VERSION "HIPBNYYYYYYYYYYYYYYYYYYYYYYYYYYYYYYYYYYYYY/4/%%%/4/'%**4YYY///"

NS_ :

BS_:

BU_: DBG VCU BMS MCM DCU DAQ S2C

BO_ 256 EMeter_Measurement: 8 Vector__XXX
 SG_ EMeter_Current : 7|32@0- (1.5258789063e-005,0) [0|0] "A" Vector__XXX
 SG_ EMeter_Voltage : 39|32@0- (1.5258789063e-005,0) [0|0] "V" Vector__XXX

BO_ 165 MCM_Motor_Position_Info: 8 MCM
 SG_ MCM_Motor_Speed : 16|16@1- (1,0) [-32768|32767] "RPM" VCU

BO_ 166 MCM_Current_Info: 8 MCM
 SG_ MCM_DC_Bus_Current : 48|16@1- (0.1,0) [-3276.8|3276.7] "A" VCU

BO_ 167 MCM_Voltage_Info: 8 MCM
 SG_ MCM_DC_Bus_Voltage : 0|16@1- (0.1,0) [-3276.8|3276.7] "V" VCU

BO_ 170 MCM_Internal_States: 8 MCM
 SG_ MCM_Int_Invert_Enable_State : 48|1@1+ (1,0) [0|1] "" MCM
 SG_ MCM_Int_Inverter_State : 16|8@1+ (1,0) [0|255] "" MCM

BO_ 172 MCM_Torque_And_Timer_Info: 8 MCM
 SG_ MCM_Torque_Feedback : 16|16@1- (0.1,0) [-3276.8|3276.7] "Nm" VCU
 SG_ MCM_Commanded_Torque : 0|16@1- (0.1,0) [-3276.8|3276.7] "Nm" VCU

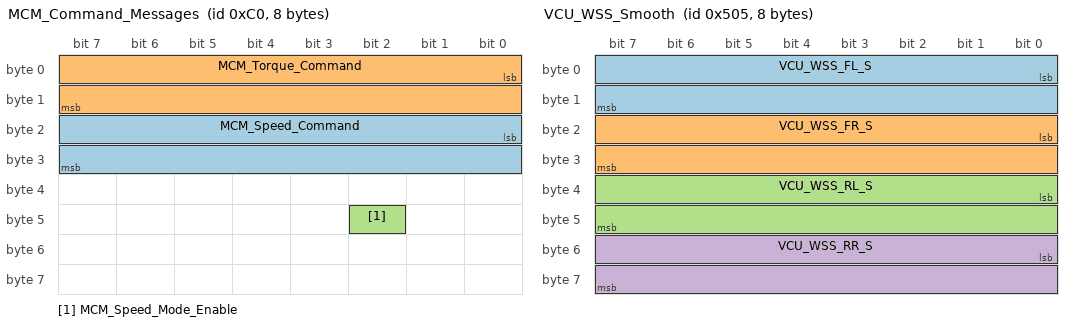
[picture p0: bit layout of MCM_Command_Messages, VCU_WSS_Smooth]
BO_ 192 MCM_Command_Messages: 8 VCU
 SG_ MCM_Speed_Command : 16|16@1- (1,0) [-32768|32767] "rpm" MCM
 SG_ MCM_Torque_Command : 0|16@1- (0.1,0) [-3276.8|3276.7] "Nm" MCM
 SG_ MCM_Speed_Mode_Enable : 42|1@1+ (1,0) [0|1] "" MCM

BO_ 1281 VCU_TPS1: 8 VCU
 SG_ ThrottlePercent0FF : 0|8@1+ (1,0) [0|255] "" VCU

BO_ 1282 VCU_BPS0: 8 VCU
SG_ BrakePercent0FF : 0|8@1+ (0.392156862746,0) [0|100.00000000023] "%" VCU

BO_ 1285 VCU_WSS_Smooth: 8 VCU
 SG_ VCU_WSS_FL_S : 0|16@1+ (1,0) [0|32767] "RPM" VCU
 SG_ VCU_WSS_FR_S : 16|16@1+ (1,0) [0|32767] "RPM" VCU
 SG_ VCU_WSS_RL_S : 32|16@1+ (1,0) [0|32767] "RPM" VCU
 SG_ VCU_WSS_RR_S : 48|16@1+ (1,0) [0|32767] "RPM" VCU

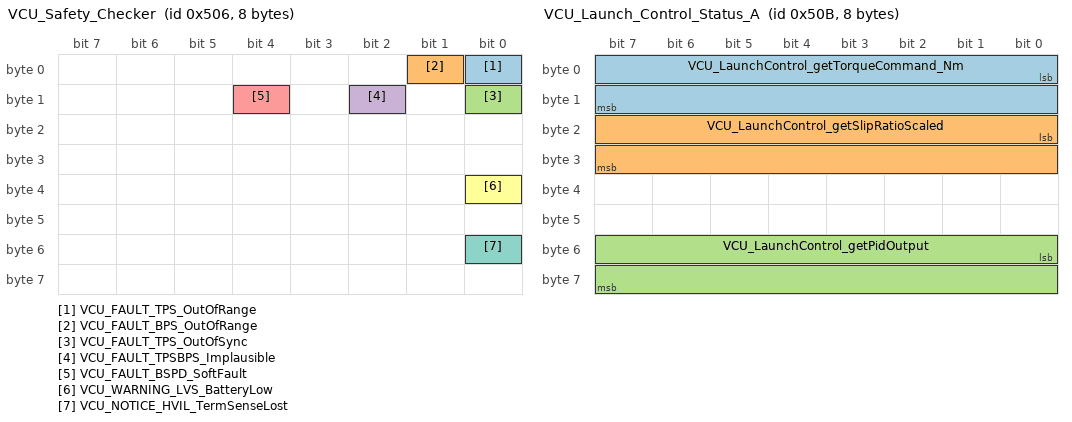
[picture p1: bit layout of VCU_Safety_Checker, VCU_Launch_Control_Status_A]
BO_ 1286 VCU_Safety_Checker: 8 VCU
 SG_ VCU_FAULT_TPS_OutOfRange : 0|1@1+ (1,0) [0|1] "" VCU
 SG_ VCU_FAULT_BPS_OutOfRange : 1|1@1+ (1,0) [0|1] "" VCU
 SG_ VCU_FAULT_TPS_OutOfSync : 8|1@1+ (1,0) [0|1] "" VCU
 SG_ VCU_FAULT_TPSBPS_Implausible : 10|1@1+ (1,0) [0|1] "" VCU
 SG_ VCU_FAULT_BSPD_SoftFault : 12|1@1+ (1,0) [0|1] "" VCU
 SG_ VCU_WARNING_LVS_BatteryLow : 32|1@1+ (1,0) [0|1] "" VCU
 SG_ VCU_NOTICE_HVIL_TermSenseLost : 48|1@1+ (1,0) [0|1] "" VCU

BO_ 1287 Low_Voltage: 8 DAQ
 SG_ Voltage : 0|16@1+ (0.001,0) [0|20] "V" VCU

BO_ 1288 VCU_Regen_Settings: 8 VCU
 SG_ VCU_MCM_RegenMode : 0|8@1+ (1,0) [0|255] "" VCU
 SG_ VCU_MCM_MaxTorqueNm : 16|8@1+ (1,0) [0|255] "Nm" VCU

BO_ 1290 Ground_Speed: 8 mcm
 SG_ speedKph : 0|16@1+ (1,0) [0|200] "km/h" mcm

BO_ 1291 VCU_Launch_Control_Status_A: 8 VCU
 SG_ VCU_LaunchControl_getTorqueCommand_Nm : 0|16@1- (1,0) [-32768|32767] "Nm" VCU
 SG_ VCU_LaunchControl_getSlipRatioScaled : 16|16@1- (1,0) [-32768|32767] "" VCU
 SG_ VCU_LaunchControl_getPidOutput : 48|16@1- (1,0) [-32768|32767] "" VCU

BO_ 1292 DRS_SAS: 8 DAQ
 SG_ Steering_Angle : 0|16@1- (1,0) [-100|100] "Degrees" VCU

BO_ 1294 VCU_BMS_Debug_1: 8 VCU
 SG_ VCU_BMS_HighestCellTemp : 24|16@1+ (1,0) [0|255] "" VCU

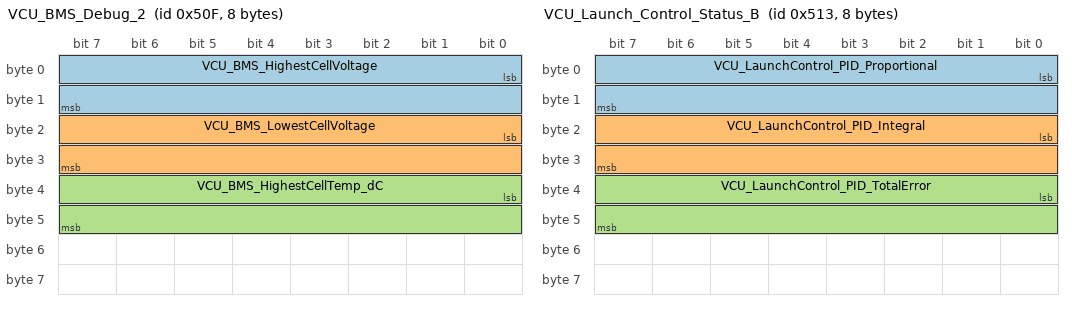
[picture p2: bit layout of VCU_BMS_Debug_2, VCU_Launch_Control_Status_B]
BO_ 1295 VCU_BMS_Debug_2: 8 VCU
 SG_ VCU_BMS_HighestCellVoltage : 0|16@1+ (1,0) [0|255] "V" VCU
 SG_ VCU_BMS_LowestCellVoltage : 16|16@1+ (1,0) [0|255] "V" VCU
 SG_ VCU_BMS_HighestCellTemp_dC : 32|16@1- (1,0) [-32768|32767] "C" VCU

BO_ 1297 VCU_Power_Limit_Status_AMsg: 8 VCU
 SG_ VCU_POWERLIMIT_PID_getTotalError : 24|16@1- (1,0) [-32768|32767] "" VCU
 SG_ VCU_POWERLIMIT_PID_getProportional : 40|16@1- (1,0) [-32768|32767] "" VCU

BO_ 1298 VCU_Power_Limit_Status_BMsg: 8 VCU
 SG_ VCU_POWERLIMIT_PID_getIntegral : 0|16@1- (1,0) [-32768|32767] "" VCU
 SG_ VCU_POWERLIMIT_getTorqueCommand_Nm : 16|16@1- (1,0) [-32768|32767] "Nm" VCU

BO_ 1299 VCU_Launch_Control_Status_B: 8 VCU
 SG_ VCU_LaunchControl_PID_Proportional : 0|16@1- (1,0) [-32768|32767] "" VCU
 SG_ VCU_LaunchControl_PID_Integral : 16|16@1- (1,0) [-32768|32767] "" VCU
 SG_ VCU_LaunchControl_PID_TotalError : 32|16@1- (1,0) [-32768|32767] "" VCU

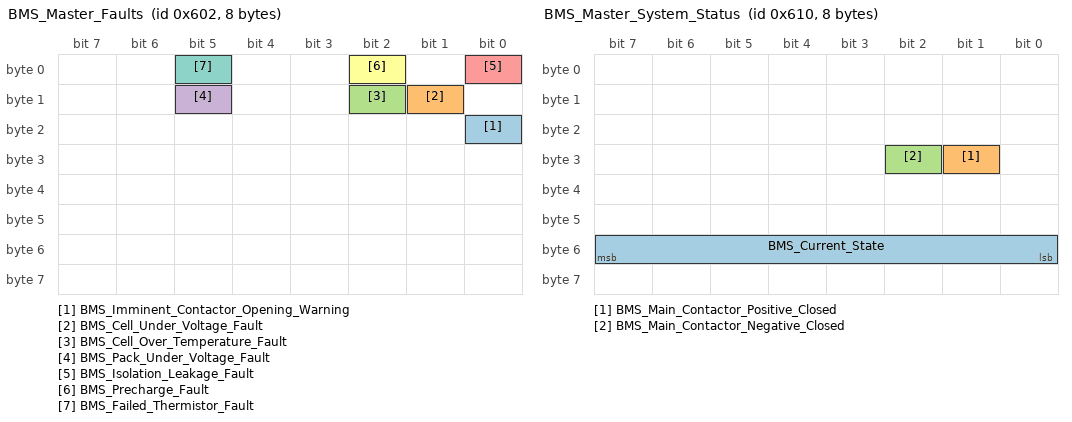
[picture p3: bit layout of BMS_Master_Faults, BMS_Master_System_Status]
BO_ 1538 BMS_Master_Faults: 8 BMS1000M
 SG_ BMS_Imminent_Contactor_Opening_Warning : 16|1@1+ (1,0) [0|1] "" Vector__XXX
 SG_ BMS_Cell_Under_Voltage_Fault : 9|1@1+ (1,0) [0|1] "" Vector__XXX
 SG_ BMS_Cell_Over_Temperature_Fault : 10|1@1+ (1,0) [0|1] "" Vector__XXX
 SG_ BMS_Pack_Under_Voltage_Fault : 13|1@1+ (1,0) [0|1] "" Vector__XXX
 SG_ BMS_Isolation_Leakage_Fault : 0|1@1+ (1,0) [0|1] "" Vector__XXX
 SG_ BMS_Precharge_Fault : 2|1@1+ (1,0) [0|1] "" Vector__XXX
 SG_ BMS_Failed_Thermistor_Fault : 5|1@1+ (1,0) [0|1] "" Vector__XXX

BO_ 1552 BMS_Master_System_Status: 8 BMS1000M
 SG_ BMS_Current_State : 48|8@1+ (1,0) [0|6] "" Vector__XXX
 SG_ BMS_Main_Contactor_Positive_Closed : 25|1@1+ (1,0) [0|1] "" Vector__XXX
 SG_ BMS_Main_Contactor_Negative_Closed : 26|1@1+ (1,0) [0|1] "" Vector__XXX

BO_ 1568 BMS_Pack_Level_Measurements_1: 8 BMS1000M
 SG_ BMS_Pack_Voltage : 32|32@1+ (0.001,0) [0|1500] "V" Vector__XXX

BO_ 1569 BMS_Pack_Level_Measurements_2: 8 BMS1000M
 SG_ BMS_State_Of_Charge : 48|16@1+ (0.1,0) [0|100] "%" Vector__XXX

BO_ 1571 BMS_Cell_Temperature_Summary: 8 BMS1000M
 SG_ BMS_Highest_Cell_Temperature : 48|16@1- (0.1,0) [-50|150] "DegC" Vector__XXX

CM_ BU_ VCU "The vehicle control unit";
CM_ BU_ MCM "The motor controller of the car";
CM_ BU_ BMS "The battery management system";
CM_ BU_ DCU "The dash control unit";
CM_ BO_ 160 "Motor Controller Temperatures Set 1";
CM_ BO_ 161 "Motor Controller Temperatures Set 2";
CM_ BO_ 162 "Motor Controller Temperatures Set 3";
CM_ BO_ 165 "Motor Position Information";
CM_ BO_ 166 "Motor Current Information";
CM_ BO_ 167 "Motor Voltage Information";
CM_ BO_ 192 "Motor Controller Command Messages";
CM_ BO_ 1280 "Throttle Position Sensor 0 Value";
CM_ BO_ 1281 "Throttle Position Sensor 1 Value";
CM_ BO_ 1282 "Brake Pressure Sensor Value";
CM_ BO_ 1283 "Wheel Speed Sensor Value";
CM_ BO_ 1286 "VCU Safety Messages";
CM_ BO_ 1568 "BMS Status and Fault Message";
CM_ BO_ 1571 "Accumulator Pack Voltage and Current";
CM_ BO_ 1572 "Accumulator Load Voltage and Current";
CM_ BO_ 1573 "Cell Voltage High and Low";
CM_ BO_ 1574 "Cell Voltage Average and Mismatch";
CM_ BO_ 1575 "SOC Percentage and Battery Capacity";
CM_ BO_ 1576 "Cell and BMS Board Temperature Average";
CM_ BO_ 1577 "Cell Temperature High and Low";
CM_ BO_ 1584 "BMS Board Temperature High and Low";
CM_ BO_ 1585 "Accumulator Load Power";
CM_ BO_ 1793 "Dash Control Unit Timestamp";
CM_ BO_ 2023 "This CAN id is used for communication between the energy meter and the download tool.";
CM_ BO_ 2031 "This CAN id is used for communication between the energy meter and the download tool.";
CM_ BU_ BMS1000M "BMS Master Controller";
CM_ BU_ VCU "Vehicle Control Unit or Master System Controller";
CM_ BO_ 1536 "Sent when BMS state transition is needed";
CM_ BO_ 1538 "Sent every 100ms";
CM_ BO_ 1552 "Sent every 100ms";
CM_ BO_ 1553 "Sent every 100ms";
CM_ BO_ 1554 "Sent every 100ms";
CM_ BO_ 1568 "Sent every 100ms";
CM_ SG_ 1568 BMS_Pack_Current "Charging is positive";
CM_ BO_ 1569 "Sent every 100ms";
CM_ BO_ 1570 "Sent every 100ms";
CM_ BO_ 1571 "Sent every 100ms";
CM_ BO_ 1788 "Sent every 1 second";
CM_ BO_ 1788 "Sent every 1 second";
CM_ BO_ 1572 "Sent every 100ms";

BA_DEF_ "BusType" STRING ;
BA_DEF_ SG_ "FieldType" STRING ;

BA_DEF_DEF_ "BusType" "CAN";
BA_DEF_DEF_ "FieldType" "";

BA_ "FieldType" SG_ 100 DRIVER_HEARTBEAT_cmd "DRIVER_HEARTBEAT_cmd";

VAL_ 100 DRIVER_HEARTBEAT_cmd 2 "DRIVER_HEARTBEAT_cmd_REBOOT" 1 "DRIVER_HEARTBEAT_cmd_SYNC" 0 "DRIVER_HEARTBEAT_cmd_NOOP" ;
VAL_ 1024 CurrentGain 0 "x1" 1 "x2" 2 "x4" 3 "x8" 4 "x16" 5 "x32" ;
VAL_ 1024 Logging 0 "x1" 1 "x2" 2 "x4" 3 "x8" 4 "x16" 5 "x32" ;/Users/sean/Downloads/NLG5_BRUSA.dbc
VAL_ 1536 BMS_State_Request 0 "No State Change Requested" 1 "Request BMS Sleep" 2 "Request BMS Idle" 3 "Request BMS Pre-charge" 4 "Request Clear Faults" ;
VAL_ 1538 BMS_Imminent_Contactor_Opening_Warning 0 "Contactors will not open within 2 seconds" 1 "Contactors will open within 2 seconds due to fault condition" ;
VAL_ 1552 BMS_Current_State 0 "BMS Internal Error" 1 "BMS Sleep" 2 "BMS Startup" 3 "BMS Idle" 4 "BMS Pre-charge" 5 "BMS Active" 6 "BMS Fault" ;
